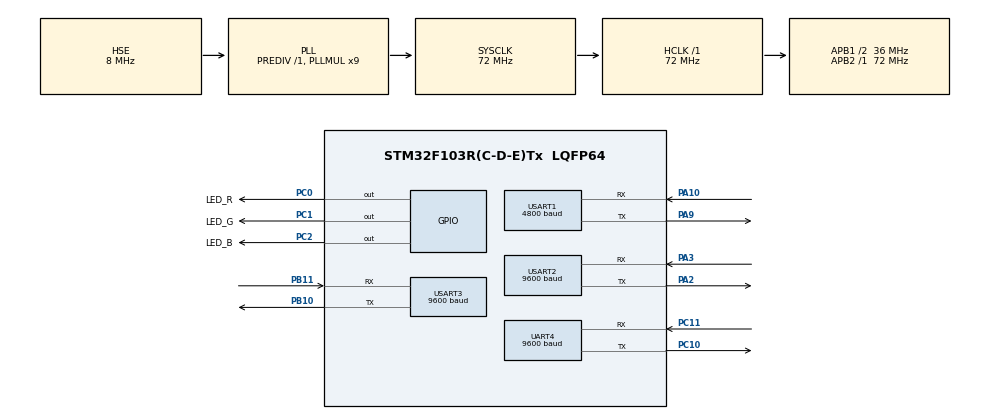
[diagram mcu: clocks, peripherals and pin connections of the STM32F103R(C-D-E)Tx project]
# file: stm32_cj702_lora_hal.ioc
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Mcu.Family=STM32F1
Mcu.Name=STM32F103R(C-D-E)Tx
Mcu.Package=LQFP64
NVIC.PriorityGroup=NVIC_PRIORITYGROUP_4
NVIC.TIM2_IRQn=true\:0\:0\:false\:false\:true\:true\:true\:true
NVIC.USART2_IRQn=true\:0\:0\:false\:false\:true\:true\:true\:true
PA13.Mode=Serial_Wire
PA13.Signal=SYS_JTMS-SWDIO
PA14.Mode=Serial_Wire
PA14.Signal=SYS_JTCK-SWCLK
PA9.Mode=Asynchronous
PA9.Signal=USART1_TX
PA10.Mode=Asynchronous
PA10.Signal=USART1_RX
PA2.Mode=Asynchronous
PA2.Signal=USART2_TX
PA3.Mode=Asynchronous
PA3.Signal=USART2_RX
PB10.Mode=Asynchronous
PB10.Signal=USART3_TX
PB11.Mode=Asynchronous
PB11.Signal=USART3_RX
PC10.Mode=Asynchronous
PC10.Signal=UART4_TX
PC11.Mode=Asynchronous
PC11.Signal=UART4_RX
PC0.GPIO_Label=LED_R
PC0.PinState=GPIO_PIN_SET
PC0.Signal=GPIO_Output
PC1.GPIO_Label=LED_G
PC1.PinState=GPIO_PIN_SET
PC1.Signal=GPIO_Output
PC2.GPIO_Label=LED_B
PC2.PinState=GPIO_PIN_SET
PC2.Signal=GPIO_Output
PD0-OSC_IN.Mode=HSE-External-Oscillator
PD0-OSC_IN.Signal=RCC_OSC_IN
PD1-OSC_OUT.Mode=HSE-External-Oscillator
PD1-OSC_OUT.Signal=RCC_OSC_OUT
ProjectManager.HeapSize=0x200
ProjectManager.StackSize=0x400
ProjectManager.TargetToolchain=MDK-ARM
RCC.AHBFreq_Value=72000000
RCC.APB1CLKDivider=RCC_HCLK_DIV2
RCC.APB1Freq_Value=36000000
RCC.APB1TimFreq_Value=72000000
RCC.APB2Freq_Value=72000000
RCC.APB2TimFreq_Value=72000000
RCC.HCLKFreq_Value=72000000
RCC.HSE_VALUE=8000000
RCC.PLLMUL=RCC_PLL_MUL9
RCC.PLLSourceVirtual=RCC_PLLSOURCE_HSE
RCC.SYSCLKFreq_VALUE=72000000
RCC.SYSCLKSource=RCC_SYSCLKSOURCE_PLLCLK
RCC.USBFreq_Value=72000000
TIM2.AutoReloadPreload=TIM_AUTORELOAD_PRELOAD_ENABLE
TIM2.Period=9999
TIM2.Prescaler=7199
USART1.BaudRate=4800
USART1.Mode=UART_MODE_TX_RX
USART1.Parity=UART_PARITY_NONE
USART1.StopBits=UART_STOPBITS_1
USART1.VirtualMode=VM_ASYNC
USART1.WordLength=UART_WORDLENGTH_8B
USART2.BaudRate=9600
USART2.Mode=UART_MODE_TX_RX
USART2.Parity=UART_PARITY_NONE
USART2.StopBits=UART_STOPBITS_1
USART2.VirtualMode=VM_ASYNC
USART2.WordLength=UART_WORDLENGTH_8B
USART3.BaudRate=9600
USART3.Mode=UART_MODE_TX_RX
USART3.Parity=UART_PARITY_NONE
USART3.StopBits=UART_STOPBITS_1
USART3.VirtualMode=VM_ASYNC
USART3.WordLength=UART_WORDLENGTH_8B
UART4.BaudRate=9600
UART4.Mode=UART_MODE_TX_RX
UART4.Parity=UART_PARITY_NONE
UART4.StopBits=UART_STOPBITS_1
UART4.VirtualMode=VM_ASYNC
UART4.WordLength=UART_WORDLENGTH_8B
VP_TIM2_VS_ClockSourceINT.Mode=Internal
board=custom

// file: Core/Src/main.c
/* USER CODE BEGIN Header */
/**
  ******************************************************************************
  * @file           : main.c
  * @brief          : Main program body
  ******************************************************************************
  * @attention
  *
  * Copyright (c) 2024 STMicroelectronics.
  * All rights reserved.
  *
  * This software is licensed under terms that can be found in the LICENSE file
  * in the root directory of this software component.
  * If no LICENSE file comes with this software, it is provided AS-IS.
  *
  ******************************************************************************
  */
/* USER CODE END Header */
#include "main.h"
#include "tim.h"
#include "usart.h"
#include "gpio.h"

/* USER CODE BEGIN Includes */
#include "app_fsm.h"
#include "status_led.h"
#include "leaf_sensor.h"
#include "soil_sensor.h"

extern app_fsm_t g_app_fsm;
/* USER CODE END Includes */

void SystemClock_Config(void);

int main(void)
{

  /* MCU Configuration--------------------------------------------------------*/

  /* Reset of all peripherals, Initializes the Flash interface and the Systick. */
  HAL_Init();

  /* Configure the system clock */
  SystemClock_Config();

  /* Initialize all configured peripherals */
  MX_GPIO_Init();
  MX_TIM2_Init();
  MX_USART1_UART_Init();
  MX_USART2_UART_Init();
  MX_USART3_UART_Init();
  MX_UART4_Init();
  /* USER CODE BEGIN 2 */
  HAL_TIM_Base_Start_IT(&htim2);
  status_led_init();
  status_led_set(LED_STATE_NORMAL);
  app_fsm_init(&g_app_fsm);
  /* USER CODE END 2 */

  /* Infinite loop */
  /* USER CODE BEGIN WHILE */
  while (1)
  {
    app_fsm_run(&g_app_fsm);
    /* USER CODE END WHILE */

  }
}

void SystemClock_Config(void)
{
  RCC_OscInitTypeDef RCC_OscInitStruct = {0};
  RCC_ClkInitTypeDef RCC_ClkInitStruct = {0};

  /** Initializes the RCC Oscillators according to the specified parameters
  * in the RCC_OscInitTypeDef structure.
  */
  RCC_OscInitStruct.OscillatorType = RCC_OSCILLATORTYPE_HSE;
  RCC_OscInitStruct.HSEState = RCC_HSE_ON;
  RCC_OscInitStruct.HSEPredivValue = RCC_HSE_PREDIV_DIV1;
  RCC_OscInitStruct.HSIState = RCC_HSI_ON;
  RCC_OscInitStruct.PLL.PLLState = RCC_PLL_ON;
  RCC_OscInitStruct.PLL.PLLSource = RCC_PLLSOURCE_HSE;
  RCC_OscInitStruct.PLL.PLLMUL = RCC_PLL_MUL9;
  if (HAL_RCC_OscConfig(&RCC_OscInitStruct) != HAL_OK)
  {
    Error_Handler();
  }

  /** Initializes the CPU, AHB and APB buses clocks
  */
  RCC_ClkInitStruct.ClockType = RCC_CLOCKTYPE_HCLK|RCC_CLOCKTYPE_SYSCLK
                              |RCC_CLOCKTYPE_PCLK1|RCC_CLOCKTYPE_PCLK2;
  RCC_ClkInitStruct.SYSCLKSource = RCC_SYSCLKSOURCE_PLLCLK;
  RCC_ClkInitStruct.AHBCLKDivider = RCC_SYSCLK_DIV1;
  RCC_ClkInitStruct.APB1CLKDivider = RCC_HCLK_DIV2;
  RCC_ClkInitStruct.APB2CLKDivider = RCC_HCLK_DIV1;

  if (HAL_RCC_ClockConfig(&RCC_ClkInitStruct, FLASH_LATENCY_2) != HAL_OK)
  {
    Error_Handler();
  }
}

void Error_Handler(void)
{
  __disable_irq();
  while (1)
  {
  }
}

#ifdef USE_FULL_ASSERT
/**
  * @brief  Reports the name of the source file and the source line number
  *         where the assert_param error has occurred.
  * @param  file: pointer to the source file name
  * @param  line: assert_param error line number
  * @retval None
  */
void assert_failed(uint8_t *file, uint32_t line)
{
  /* USER CODE BEGIN 6 */
  (void)file;
  (void)line;
  /* USER CODE END 6 */
}
#endif /* USE_FULL_ASSERT */
